# CC23x0 register map
File version: 1.1
CPU: CM0+ r0p4, little endian, no MPU, no FPU, VTOR, 3 interrupt priority bits
Registers are 32-bit, read-write, reset 0x0 unless marked. A register's access mark holds for its fields unless they carry their own. Offsets are from the block's base; [hi:lo] are bit positions; {n}, {i} and the like mark numbered series; 'fields as' and 'values as' point back to an identical list.

## LRFDMDM32 (part 2 of 2)
Base 0x40082400
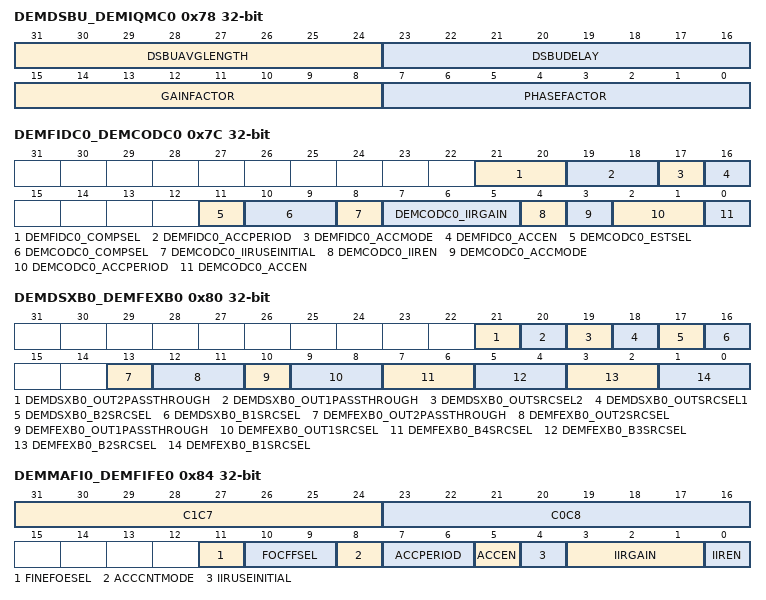
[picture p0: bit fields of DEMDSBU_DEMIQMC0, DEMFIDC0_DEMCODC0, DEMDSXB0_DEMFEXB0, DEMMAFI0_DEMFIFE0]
0x78 DEMDSBU_DEMIQMC0 — Internal. Only to be used through TI provided API.
  [all] fields
    255=ALLONES (Internal. Only to be used through TI provided API.); 0=ALLZEROS (Internal. Only to be used through TI provided API.)
  [31:24] DSBUAVGLENGTH — Internal. Only to be used through TI provided API.
  [23:16] DSBUDELAY — Internal. Only to be used through TI provided API.
  [15:8] GAINFACTOR — Internal. Only to be used through TI provided API.
  [7:0] PHASEFACTOR — Internal. Only to be used through TI provided API.
0x7C DEMFIDC0_DEMCODC0 — Internal. Only to be used through TI provided API.
  [21:20] DEMFIDC0_COMPSEL — Internal. Only to be used through TI provided API.
    2=ACC (Internal. Only to be used through TI provided API.); 0=MANUAL (Internal. Only to be used through TI provided API.)
  [19:18] DEMFIDC0_ACCPERIOD — Internal. Only to be used through TI provided API.
    3=SMPL512 (Internal. Only to be used through TI provided API.); 2=SMPL128 (Internal. Only to be used through TI provided API.); 1=SMPL32 (Internal. Only to be used through TI provided API.); 0=SMPL8 (Internal. Only to be used through TI provided API.)
  [17] DEMFIDC0_ACCMODE — Internal. Only to be used through TI provided API.
    1=CONT (Internal. Only to be used through TI provided API.); 0=SINGLE (Internal. Only to be used through TI provided API.)
  [16] DEMFIDC0_ACCEN — Internal. Only to be used through TI provided API.
    1=ON (Internal. Only to be used through TI provided API.); 0=OFF (Internal. Only to be used through TI provided API.)
  [11] DEMCODC0_ESTSEL — Internal. Only to be used through TI provided API.
    1=IIR (Internal. Only to be used through TI provided API.); 0=ACC (Internal. Only to be used through TI provided API.)
  [10:9] DEMCODC0_COMPSEL — Internal. Only to be used through TI provided API.
    3=IIR (Internal. Only to be used through TI provided API.); 2=ACC (Internal. Only to be used through TI provided API.); 0=MANUAL (Internal. Only to be used through TI provided API.)
  [8] DEMCODC0_IIRUSEINITIAL — Internal. Only to be used through TI provided API.
    1=EN (Internal. Only to be used through TI provided API.); 0=DIS (Internal. Only to be used through TI provided API.)
  [7:5] DEMCODC0_IIRGAIN — Internal. Only to be used through TI provided API.
    7=DIV1024 (Internal. Only to be used through TI provided API.); 6=DIV512 (Internal. Only to be used through TI provided API.); 5=DIV256 (Internal. Only to be used through TI provided API.); 4=DIV128 (Internal. Only to be used through TI provided API.); 3=DIV64 (Internal. Only to be used through TI provided API.); 2=DIV32 (Internal. Only to be used through TI provided API.); 1=DIV16 (Internal. Only to be used through TI provided API.); 0=OFF (Internal. Only to be used through TI provided API.)
  [4] DEMCODC0_IIREN — Internal. Only to be used through TI provided API.
    values as DEMFIDC0_ACCEN
  [3] DEMCODC0_ACCMODE — Internal. Only to be used through TI provided API.
    values as DEMFIDC0_ACCMODE
  [2:1] DEMCODC0_ACCPERIOD — Internal. Only to be used through TI provided API.
    values as DEMFIDC0_ACCPERIOD
  [0] DEMCODC0_ACCEN — Internal. Only to be used through TI provided API.
    values as DEMFIDC0_ACCEN
0x80 DEMDSXB0_DEMFEXB0 — Internal. Only to be used through TI provided API.
  [21] DEMDSXB0_OUT2PASSTHROUGH — Internal. Only to be used through TI provided API.
    1=ONE (Internal. Only to be used through TI provided API.); 0=ZERO (Internal. Only to be used through TI provided API.)
  [20] DEMDSXB0_OUT1PASSTHROUGH — Internal. Only to be used through TI provided API.
    values as DEMDSXB0_OUT2PASSTHROUGH
  [19] DEMDSXB0_OUTSRCSEL2 — Internal. Only to be used through TI provided API.
    1=MAFI (Internal. Only to be used through TI provided API.); 0=FIFE (Internal. Only to be used through TI provided API.)
  [18] DEMDSXB0_OUTSRCSEL1 — Internal. Only to be used through TI provided API.
    values as DEMDSXB0_OUTSRCSEL2
  [17] DEMDSXB0_B2SRCSEL — Internal. Only to be used through TI provided API.
    1=FIFE (Internal. Only to be used through TI provided API.); 0=INPUT (Internal. Only to be used through TI provided API.)
  [16] DEMDSXB0_B1SRCSEL — Internal. Only to be used through TI provided API.
    1=MAFI (Internal. Only to be used through TI provided API.); 0=INPUT (Internal. Only to be used through TI provided API.)
  [13] DEMFEXB0_OUT2PASSTHROUGH — Internal. Only to be used through TI provided API.
    values as DEMDSXB0_OUT2PASSTHROUGH
  [12:11] DEMFEXB0_OUT2SRCSEL — Internal. Only to be used through TI provided API.
    2=BDE1 (Internal. Only to be used through TI provided API.); 1=CMIX (Internal. Only to be used through TI provided API.); 0=CODC (Internal. Only to be used through TI provided API.)
  [10] DEMFEXB0_OUT1PASSTHROUGH — Internal. Only to be used through TI provided API.
    values as DEMDSXB0_OUT2PASSTHROUGH
  [9:8] DEMFEXB0_OUT1SRCSEL — Internal. Only to be used through TI provided API.
    values as DEMFEXB0_OUT2SRCSEL
  [7:6] DEMFEXB0_B4SRCSEL — Internal. Only to be used through TI provided API.
    3=ONES (Internal. Only to be used through TI provided API.); 0=ZEROS (Internal. Only to be used through TI provided API.)
  [5:4] DEMFEXB0_B3SRCSEL — Internal. Only to be used through TI provided API.
    2=CMIX (Internal. Only to be used through TI provided API.); 1=CODC (Internal. Only to be used through TI provided API.); 0=INPUT (Internal. Only to be used through TI provided API.)
  [3:2] DEMFEXB0_B2SRCSEL — Internal. Only to be used through TI provided API.
    2=BDE1 (Internal. Only to be used through TI provided API.); 1=CODC (Internal. Only to be used through TI provided API.); 0=INPUT (Internal. Only to be used through TI provided API.)
  [1:0] DEMFEXB0_B1SRCSEL — Internal. Only to be used through TI provided API.
    2=BDE1 (Internal. Only to be used through TI provided API.); 1=CMIX (Internal. Only to be used through TI provided API.); 0=INPUT (Internal. Only to be used through TI provided API.)
0x84 DEMMAFI0_DEMFIFE0 — Internal. Only to be used through TI provided API.
  [31:24] C1C7 — Internal. Only to be used through TI provided API.
    values as the fields of DEMDSBU_DEMIQMC0
  [23:16] C0C8 — Internal. Only to be used through TI provided API.
    values as the fields of DEMDSBU_DEMIQMC0
  [11] FINEFOESEL — Internal. Only to be used through TI provided API.
    1=ACC (Internal. Only to be used through TI provided API.); 0=IIR (Internal. Only to be used through TI provided API.)
  [10:9] FOCFFSEL — Internal. Only to be used through TI provided API.
    2=MANUAL (Internal. Only to be used through TI provided API.); 1=ACC (Internal. Only to be used through TI provided API.); 0=IIR (Internal. Only to be used through TI provided API.)
  [8] ACCCNTMODE — Internal. Only to be used through TI provided API.
    values as DEMFIDC0_DEMCODC0.DEMFIDC0_ACCMODE
  [7:6] ACCPERIOD — Internal. Only to be used through TI provided API.
    3=PER512 (Internal. Only to be used through TI provided API.); 2=PER256 (Internal. Only to be used through TI provided API.); 1=PER128 (Internal. Only to be used through TI provided API.); 0=PER64 (Internal. Only to be used through TI provided API.)
  [5] ACCEN — Internal. Only to be used through TI provided API.
    values as DEMFIDC0_DEMCODC0.DEMFIDC0_ACCEN
  [4] IIRUSEINITIAL — Internal. Only to be used through TI provided API.
    values as DEMFIDC0_DEMCODC0.DEMCODC0_IIRUSEINITIAL
  [3:1] IIRGAIN — Internal. Only to be used through TI provided API.
    values as DEMFIDC0_DEMCODC0.DEMCODC0_IIRGAIN
  [0] IIREN — Internal. Only to be used through TI provided API.
    values as DEMFIDC0_DEMCODC0.DEMFIDC0_ACCEN
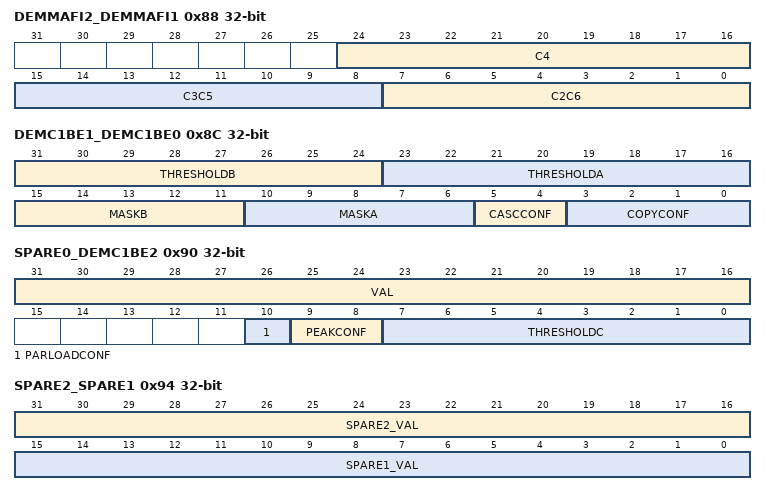
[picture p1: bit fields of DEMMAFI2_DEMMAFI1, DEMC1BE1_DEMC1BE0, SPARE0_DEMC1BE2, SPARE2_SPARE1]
0x88 DEMMAFI2_DEMMAFI1 — Internal. Only to be used through TI provided API.
  [24:16] C4 — Internal. Only to be used through TI provided API.
    0x1FF=ALLONES (Internal. Only to be used through TI provided API.); 0=ALLZEROS (Internal. Only to be used through TI provided API.)
  [15:8] C3C5 — Internal. Only to be used through TI provided API.
    values as the fields of DEMDSBU_DEMIQMC0
  [7:0] C2C6 — Internal. Only to be used through TI provided API.
    values as the fields of DEMDSBU_DEMIQMC0
0x8C DEMC1BE1_DEMC1BE0 — Internal. Only to be used through TI provided API.
  [31:24] THRESHOLDB — Internal. Only to be used through TI provided API.
    values as the fields of DEMDSBU_DEMIQMC0
  [23:16] THRESHOLDA — Internal. Only to be used through TI provided API.
    values as the fields of DEMDSBU_DEMIQMC0
  [15:11] MASKB — Internal. Only to be used through TI provided API.
    31=ALLONES (Internal. Only to be used through TI provided API.); 0=ALLZEROS (Internal. Only to be used through TI provided API.)
  [10:6] MASKA — Internal. Only to be used through TI provided API.
    values as MASKB
  [5:4] CASCCONF — Internal. Only to be used through TI provided API.
    2=PARALLEL (Internal. Only to be used through TI provided API.); 1=SERIAL (Internal. Only to be used through TI provided API.); 0=SINGLE (Internal. Only to be used through TI provided API.)
  [3:0] COPYCONF — Internal. Only to be used through TI provided API.
    15=ALLONES (Internal. Only to be used through TI provided API.); 0=ALLZEROS (Internal. Only to be used through TI provided API.)
0x90 SPARE0_DEMC1BE2 — Internal. Only to be used through TI provided API.
  [31:16] VAL — Internal. Only to be used through TI provided API.
    0xFFFF=ALLONES (Internal. Only to be used through TI provided API.); 0=ALLZEROS (Internal. Only to be used through TI provided API.)
  [10] PARLOADCONF — Internal. Only to be used through TI provided API.
    1=ATOD (Internal. Only to be used through TI provided API.); 0=ATOB (Internal. Only to be used through TI provided API.)
  [9:8] PEAKCONF — Internal. Only to be used through TI provided API.
    2=BESTAB (Internal. Only to be used through TI provided API.); 1=BEST (Internal. Only to be used through TI provided API.); 0=THRESH (Internal. Only to be used through TI provided API.)
  [7:0] THRESHOLDC — Internal. Only to be used through TI provided API.
    values as the fields of DEMDSBU_DEMIQMC0
0x94 SPARE2_SPARE1 — Internal. Only to be used through TI provided API.
  [31:16] SPARE2_VAL — Internal. Only to be used through TI provided API.
    values as SPARE0_DEMC1BE2.VAL
  [15:0] SPARE1_VAL — Internal. Only to be used through TI provided API.
    values as SPARE0_DEMC1BE2.VAL
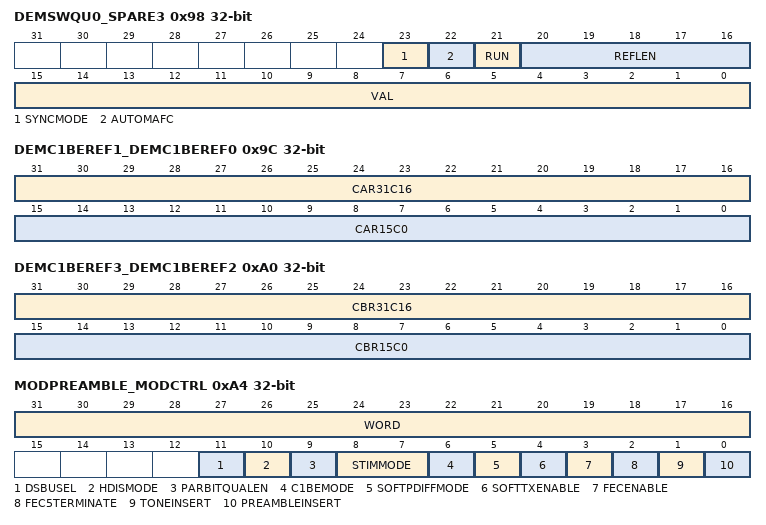
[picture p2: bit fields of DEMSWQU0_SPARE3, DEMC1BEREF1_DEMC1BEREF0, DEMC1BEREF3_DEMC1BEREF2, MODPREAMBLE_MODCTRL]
0x98 DEMSWQU0_SPARE3 — Internal. Only to be used through TI provided API.
  [23] SYNCMODE — Internal. Only to be used through TI provided API.
    values as DEMDSXB0_DEMFEXB0.DEMDSXB0_OUT2PASSTHROUGH
  [22] AUTOMAFC — Internal. Only to be used through TI provided API.
    values as DEMFIDC0_DEMCODC0.DEMFIDC0_ACCEN
  [21] RUN — Internal. Only to be used through TI provided API.
    values as DEMFIDC0_DEMCODC0.DEMFIDC0_ACCEN
  [20:16] REFLEN — Internal. Only to be used through TI provided API.
    values as DEMC1BE1_DEMC1BE0.MASKB
  [15:0] VAL — Internal. Only to be used through TI provided API.
    values as SPARE0_DEMC1BE2.VAL
0x9C DEMC1BEREF1_DEMC1BEREF0 — Internal. Only to be used through TI provided API.
  [31:16] CAR31C16 — Internal. Only to be used through TI provided API.
    values as SPARE0_DEMC1BE2.VAL
  [15:0] CAR15C0 — Internal. Only to be used through TI provided API.
    values as SPARE0_DEMC1BE2.VAL
0xA0 DEMC1BEREF3_DEMC1BEREF2 — Internal. Only to be used through TI provided API.
  [31:16] CBR31C16 — Internal. Only to be used through TI provided API.
    values as SPARE0_DEMC1BE2.VAL
  [15:0] CBR15C0 — Internal. Only to be used through TI provided API.
    values as SPARE0_DEMC1BE2.VAL
0xA4 MODPREAMBLE_MODCTRL — Internal. Only to be used through TI provided API.
  [31:16] WORD — Internal. Only to be used through TI provided API.
    values as SPARE0_DEMC1BE2.VAL
  [11] DSBUSEL — Internal. Only to be used through TI provided API.
    values as DEMDSXB0_DEMFEXB0.DEMDSXB0_OUT2PASSTHROUGH
  [10] HDISMODE — Internal. Only to be used through TI provided API.
    values as DEMFIDC0_DEMCODC0.DEMCODC0_IIRUSEINITIAL
  [9] PARBITQUALEN — Internal. Only to be used through TI provided API.
    values as DEMFIDC0_DEMCODC0.DEMFIDC0_ACCEN
  [8:7] STIMMODE — Internal. Only to be used through TI provided API.
    2=EARLY (Internal. Only to be used through TI provided API.); 1=LATE (Internal. Only to be used through TI provided API.); 0=NORMAL (Internal. Only to be used through TI provided API.)
  [6] C1BEMODE — Internal. Only to be used through TI provided API.
    1=EARLYLATE (Internal. Only to be used through TI provided API.); 0=NORMAL (Internal. Only to be used through TI provided API.)
  [5] SOFTPDIFFMODE — Internal. Only to be used through TI provided API.
    values as DEMFIDC0_DEMCODC0.DEMCODC0_IIRUSEINITIAL
  [4] SOFTTXENABLE — Internal. Only to be used through TI provided API.
    values as DEMFIDC0_DEMCODC0.DEMFIDC0_ACCEN
  [3] FECENABLE — Internal. Only to be used through TI provided API.
    values as DEMFIDC0_DEMCODC0.DEMFIDC0_ACCEN
  [2] FEC5TERMINATE — Internal. Only to be used through TI provided API.
    values as DEMFIDC0_DEMCODC0.DEMFIDC0_ACCEN
  [1] TONEINSERT — Internal. Only to be used through TI provided API.
    values as DEMFIDC0_DEMCODC0.DEMCODC0_IIRUSEINITIAL
  [0] PREAMBLEINSERT — Internal. Only to be used through TI provided API.
    values as DEMFIDC0_DEMCODC0.DEMCODC0_IIRUSEINITIAL
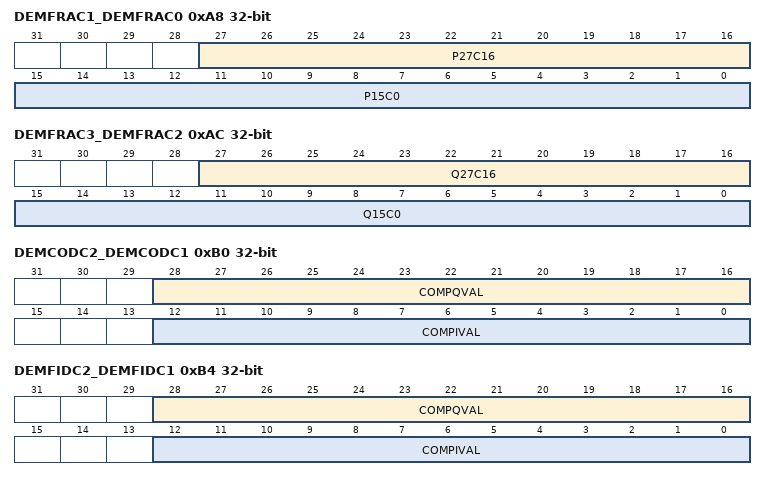
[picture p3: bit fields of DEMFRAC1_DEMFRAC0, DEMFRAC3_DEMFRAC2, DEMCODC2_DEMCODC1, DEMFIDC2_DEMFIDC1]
0xA8 DEMFRAC1_DEMFRAC0 — Internal. Only to be used through TI provided API.
  [27:16] P27C16 — Internal. Only to be used through TI provided API.
    0xFFF=ALLONES (Internal. Only to be used through TI provided API.); 0=ALLZEROS (Internal. Only to be used through TI provided API.)
  [15:0] P15C0 — Internal. Only to be used through TI provided API.
    values as SPARE0_DEMC1BE2.VAL
0xAC DEMFRAC3_DEMFRAC2 — Internal. Only to be used through TI provided API.
  [27:16] Q27C16 — Internal. Only to be used through TI provided API.
    values as DEMFRAC1_DEMFRAC0.P27C16
  [15:0] Q15C0 — Internal. Only to be used through TI provided API.
    values as SPARE0_DEMC1BE2.VAL
0xB0 DEMCODC2_DEMCODC1 — Internal. Only to be used through TI provided API.
  [28:16] COMPQVAL — Internal. Only to be used through TI provided API.
    0x1FFF=ALLONES (Internal. Only to be used through TI provided API.); 0=ALLZEROS (Internal. Only to be used through TI provided API.)
  [12:0] COMPIVAL — Internal. Only to be used through TI provided API.
    values as COMPQVAL
0xB4 DEMFIDC2_DEMFIDC1 — Internal. Only to be used through TI provided API.
  fields as DEMCODC2_DEMCODC1
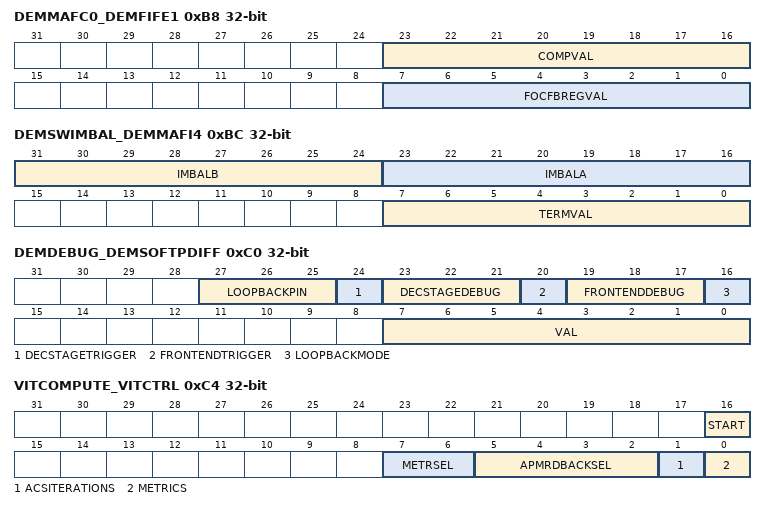
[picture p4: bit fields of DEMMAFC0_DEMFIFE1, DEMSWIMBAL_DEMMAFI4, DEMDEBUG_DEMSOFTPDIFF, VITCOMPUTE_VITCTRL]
0xB8 DEMMAFC0_DEMFIFE1 — Internal. Only to be used through TI provided API.
  [23:16] COMPVAL — Internal. Only to be used through TI provided API.
    values as the fields of DEMDSBU_DEMIQMC0
  [7:0] FOCFBREGVAL — Internal. Only to be used through TI provided API.
    values as the fields of DEMDSBU_DEMIQMC0
0xBC DEMSWIMBAL_DEMMAFI4 — Internal. Only to be used through TI provided API.
  [all] fields
    values as the fields of DEMDSBU_DEMIQMC0
  [31:24] IMBALB — Internal. Only to be used through TI provided API.
  [23:16] IMBALA — Internal. Only to be used through TI provided API.
  [7:0] TERMVAL — Internal. Only to be used through TI provided API.
0xC0 DEMDEBUG_DEMSOFTPDIFF — Internal. Only to be used through TI provided API.
  [27:25] LOOPBACKPIN — Internal. Only to be used through TI provided API.
    {v}=GPI{v} (Internal. Only to be used through TI provided API.) (v=0..7)
  [24] DECSTAGETRIGGER — Internal. Only to be used through TI provided API.
    values as DEMDSXB0_DEMFEXB0.DEMDSXB0_OUT2PASSTHROUGH
  [23:21] DECSTAGEDEBUG — Internal. Only to be used through TI provided API.
    7=SOFD (Internal. Only to be used through TI provided API.); 6=STIM (Internal. Only to be used through TI provided API.); 5=MAFC (Internal. Only to be used through TI provided API.); 4=C1BE (Internal. Only to be used through TI provided API.); 3=MAFI (Internal. Only to be used through TI provided API.); 2=FIFE (Internal. Only to be used through TI provided API.); 1=PDIF (Internal. Only to be used through TI provided API.); 0=NOSEL (Internal. Only to be used through TI provided API.)
  [20] FRONTENDTRIGGER — Internal. Only to be used through TI provided API.
    values as DEMDSXB0_DEMFEXB0.DEMDSXB0_OUT2PASSTHROUGH
  [19:17] FRONTENDDEBUG — Internal. Only to be used through TI provided API.
    7=FIDC (Internal. Only to be used through TI provided API.); 6=FRAC (Internal. Only to be used through TI provided API.); 5=CHFI (Internal. Only to be used through TI provided API.); 4=BDE2 (Internal. Only to be used through TI provided API.); 3=FEXB2 (Internal. Only to be used through TI provided API.); 2=BDE1 (Internal. Only to be used through TI provided API.); 1=IQMC (Internal. Only to be used through TI provided API.); 0=NOSEL (Internal. Only to be used through TI provided API.)
  [16] LOOPBACKMODE — Internal. Only to be used through TI provided API.
    values as DEMDSXB0_DEMFEXB0.DEMDSXB0_OUT2PASSTHROUGH
  [7:0] VAL — Internal. Only to be used through TI provided API.
    values as the fields of DEMDSBU_DEMIQMC0
0xC4 VITCOMPUTE_VITCTRL — Internal. Only to be used through TI provided API.
  [16] START wo — Internal. Only to be used through TI provided API.
    values as DEMDSXB0_DEMFEXB0.DEMDSXB0_OUT2PASSTHROUGH
  [7:6] METRSEL — Internal. Only to be used through TI provided API.
    3=MLSE (Internal. Only to be used through TI provided API.); 2=SOFD (Internal. Only to be used through TI provided API.); 1=PHAC (Internal. Only to be used through TI provided API.); 0=MET5M (Internal. Only to be used through TI provided API.)
  [5:2] APMRDBACKSEL — Internal. Only to be used through TI provided API.
    {v}=APM{v-8} (Internal. Only to be used through TI provided API.) (v=8..15); 0=NOSEL (Internal. Only to be used through TI provided API.)
  [1] ACSITERATIONS — Internal. Only to be used through TI provided API.
    1=CODE23 (Internal. Only to be used through TI provided API.); 0=CODE12 (Internal. Only to be used through TI provided API.)
  [0] METRICS — Internal. Only to be used through TI provided API.
    1=SOFT (Internal. Only to be used through TI provided API.); 0=HW (Internal. Only to be used through TI provided API.)
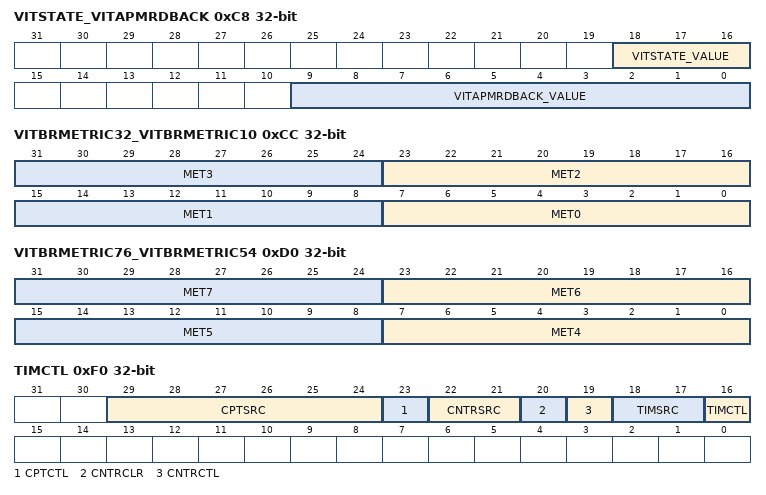
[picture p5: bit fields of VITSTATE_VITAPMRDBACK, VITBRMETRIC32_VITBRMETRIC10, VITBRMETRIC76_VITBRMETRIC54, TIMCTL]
0xC8 VITSTATE_VITAPMRDBACK ro — Internal. Only to be used through TI provided API.
  [18:16] VITSTATE_VALUE — Internal. Only to be used through TI provided API.
    7=ALLONES (Internal. Only to be used through TI provided API.); 0=ALLZEROS (Internal. Only to be used through TI provided API.)
  [9:0] VITAPMRDBACK_VALUE — Internal. Only to be used through TI provided API.
    0x3FF=ALLONES (Internal. Only to be used through TI provided API.); 0=ALLZEROS (Internal. Only to be used through TI provided API.)
0xCC VITBRMETRIC32_VITBRMETRIC10 — Internal. Only to be used through TI provided API.
  [all] fields
    values as the fields of DEMDSBU_DEMIQMC0
  [8n+7:8n] MET{n} (n=0..3) — Internal. Only to be used through TI provided API.
0xD0 VITBRMETRIC76_VITBRMETRIC54 — Internal. Only to be used through TI provided API.
  [all] fields
    values as the fields of DEMDSBU_DEMIQMC0
  [8n-25:8n-32] MET{n} (n=4..7) — Internal. Only to be used through TI provided API.
0xF0 TIMCTL — Internal. Only to be used through TI provided API.
  [29:24] CPTSRC — Internal. Only to be used through TI provided API.
    63=ALLONES (Internal. Only to be used through TI provided API.); 0=ALLZEROS (Internal. Only to be used through TI provided API.)
  [23] CPTCTL — Internal. Only to be used through TI provided API.
    values as DEMFIDC0_DEMCODC0.DEMCODC0_IIRUSEINITIAL
  [22:21] CNTRSRC — Internal. Only to be used through TI provided API.
    3=CLK4BAUDF (Internal. Only to be used through TI provided API.); 2=CLK4BAUD (Internal. Only to be used through TI provided API.); 1=CLKBAUD (Internal. Only to be used through TI provided API.); 0=CLK (Internal. Only to be used through TI provided API.)
  [20] CNTRCLR — Internal. Only to be used through TI provided API.
    values as DEMDSXB0_DEMFEXB0.DEMDSXB0_OUT2PASSTHROUGH
  [19] CNTRCTL — Internal. Only to be used through TI provided API.
    values as DEMDSXB0_DEMFEXB0.DEMDSXB0_OUT2PASSTHROUGH
  [18:17] TIMSRC — Internal. Only to be used through TI provided API.
    values as CNTRSRC
  [16] TIMCTL — Internal. Only to be used through TI provided API.
    values as DEMFIDC0_DEMCODC0.DEMCODC0_IIRUSEINITIAL
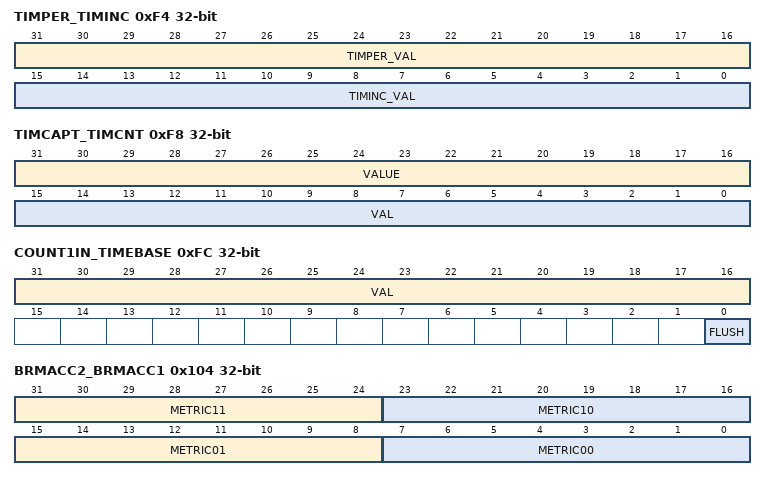
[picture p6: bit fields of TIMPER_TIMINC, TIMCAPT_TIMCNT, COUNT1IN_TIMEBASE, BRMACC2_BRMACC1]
0xF4 TIMPER_TIMINC — Internal. Only to be used through TI provided API.
  [31:16] TIMPER_VAL — Internal. Only to be used through TI provided API.
    values as SPARE0_DEMC1BE2.VAL
  [15:0] TIMINC_VAL — Internal. Only to be used through TI provided API.
    values as SPARE0_DEMC1BE2.VAL
0xF8 TIMCAPT_TIMCNT ro — Internal. Only to be used through TI provided API.
  [31:16] VALUE — Internal. Only to be used through TI provided API.
    values as SPARE0_DEMC1BE2.VAL
  [15:0] VAL — Internal. Only to be used through TI provided API.
    values as SPARE0_DEMC1BE2.VAL
0xFC COUNT1IN_TIMEBASE wo — Internal. Only to be used through TI provided API.
  [31:16] VAL — Internal. Only to be used through TI provided API.
    values as SPARE0_DEMC1BE2.VAL
  [0] FLUSH — Internal. Only to be used through TI provided API.
    values as DEMDSXB0_DEMFEXB0.DEMDSXB0_OUT2PASSTHROUGH
0x100 COUNT1RES ro — Internal. Only to be used through TI provided API.
  [4:0] VAL
    values as DEMC1BE1_DEMC1BE0.MASKB
0x104 BRMACC2_BRMACC1 ro — Internal. Only to be used through TI provided API.
  [all] fields
    values as the fields of DEMDSBU_DEMIQMC0
  [31:24] METRIC11 — Internal. Only to be used through TI provided API.
  [23:16] METRIC10 — Internal. Only to be used through TI provided API.
  [15:8] METRIC01 — Internal. Only to be used through TI provided API.
  [7:0] METRIC00 — Internal. Only to be used through TI provided API.
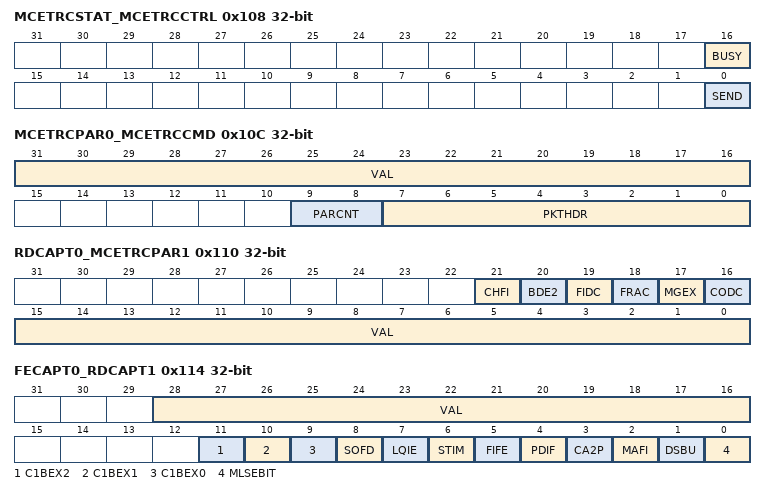
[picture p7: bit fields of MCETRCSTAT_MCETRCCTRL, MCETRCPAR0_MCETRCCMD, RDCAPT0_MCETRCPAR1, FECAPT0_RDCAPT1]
0x108 MCETRCSTAT_MCETRCCTRL wo — Internal. Only to be used through TI provided API.
  [16] BUSY ro — Internal. Only to be used through TI provided API.
    values as DEMDSXB0_DEMFEXB0.DEMDSXB0_OUT2PASSTHROUGH
  [0] SEND — Internal. Only to be used through TI provided API.
    values as DEMDSXB0_DEMFEXB0.DEMDSXB0_OUT2PASSTHROUGH
0x10C MCETRCPAR0_MCETRCCMD — Internal. Only to be used through TI provided API.
  [31:16] VAL — Internal. Only to be used through TI provided API.
    values as SPARE0_DEMC1BE2.VAL
  [9:8] PARCNT — Internal. Only to be used through TI provided API.
    3=ALLONES (Internal. Only to be used through TI provided API.); 0=ALLZEROS (Internal. Only to be used through TI provided API.)
  [7:0] PKTHDR — Internal. Only to be used through TI provided API.
    values as the fields of DEMDSBU_DEMIQMC0
0x110 RDCAPT0_MCETRCPAR1 — Internal. Only to be used through TI provided API.
  [21] CHFI wo — Internal. Only to be used through TI provided API.
    values as DEMDSXB0_DEMFEXB0.DEMDSXB0_OUT2PASSTHROUGH
  [20] BDE2 wo — Internal. Only to be used through TI provided API.
    values as DEMDSXB0_DEMFEXB0.DEMDSXB0_OUT2PASSTHROUGH
  [19] FIDC wo — Internal. Only to be used through TI provided API.
    values as DEMDSXB0_DEMFEXB0.DEMDSXB0_OUT2PASSTHROUGH
  [18] FRAC wo — Internal. Only to be used through TI provided API.
    values as DEMDSXB0_DEMFEXB0.DEMDSXB0_OUT2PASSTHROUGH
  [17] MGEX wo — Internal. Only to be used through TI provided API.
    values as DEMDSXB0_DEMFEXB0.DEMDSXB0_OUT2PASSTHROUGH
  [16] CODC wo — Internal. Only to be used through TI provided API.
    values as DEMDSXB0_DEMFEXB0.DEMDSXB0_OUT2PASSTHROUGH
  [15:0] VAL — Internal. Only to be used through TI provided API.
    values as SPARE0_DEMC1BE2.VAL
0x114 FECAPT0_RDCAPT1 wo — Internal. Only to be used through TI provided API.
  [28:16] VAL — Internal. Only to be used through TI provided API.
    values as DEMCODC2_DEMCODC1.COMPQVAL
  [11] C1BEX2 — Internal. Only to be used through TI provided API.
    values as DEMDSXB0_DEMFEXB0.DEMDSXB0_OUT2PASSTHROUGH
  [10] C1BEX1 — Internal. Only to be used through TI provided API.
    values as DEMDSXB0_DEMFEXB0.DEMDSXB0_OUT2PASSTHROUGH
  [9] C1BEX0 — Internal. Only to be used through TI provided API.
    values as DEMDSXB0_DEMFEXB0.DEMDSXB0_OUT2PASSTHROUGH
  [8] SOFD — Internal. Only to be used through TI provided API.
    values as DEMDSXB0_DEMFEXB0.DEMDSXB0_OUT2PASSTHROUGH
  [7] LQIE — Internal. Only to be used through TI provided API.
    values as DEMDSXB0_DEMFEXB0.DEMDSXB0_OUT2PASSTHROUGH
  [6] STIM — Internal. Only to be used through TI provided API.
    values as DEMDSXB0_DEMFEXB0.DEMDSXB0_OUT2PASSTHROUGH
  [5] FIFE — Internal. Only to be used through TI provided API.
    values as DEMDSXB0_DEMFEXB0.DEMDSXB0_OUT2PASSTHROUGH
  [4] PDIF — Internal. Only to be used through TI provided API.
    values as DEMDSXB0_DEMFEXB0.DEMDSXB0_OUT2PASSTHROUGH
  [3] CA2P — Internal. Only to be used through TI provided API.
    values as DEMDSXB0_DEMFEXB0.DEMDSXB0_OUT2PASSTHROUGH
  [2] MAFI — Internal. Only to be used through TI provided API.
    values as DEMDSXB0_DEMFEXB0.DEMDSXB0_OUT2PASSTHROUGH
  [1] DSBU — Internal. Only to be used through TI provided API.
    values as DEMDSXB0_DEMFEXB0.DEMDSXB0_OUT2PASSTHROUGH
  [0] MLSEBIT — Internal. Only to be used through TI provided API.
    values as DEMDSXB0_DEMFEXB0.DEMDSXB0_OUT2PASSTHROUGH
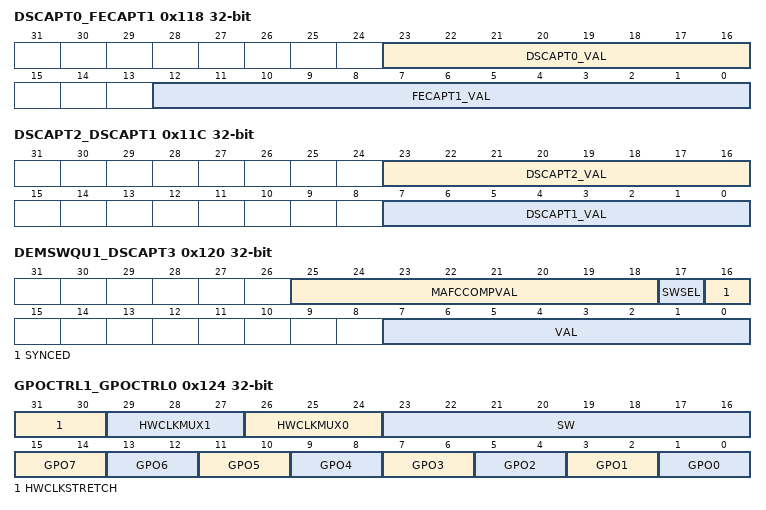
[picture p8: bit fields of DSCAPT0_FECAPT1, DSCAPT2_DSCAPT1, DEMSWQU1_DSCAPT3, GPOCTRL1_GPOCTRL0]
0x118 DSCAPT0_FECAPT1 — Internal. Only to be used through TI provided API.
  [23:16] DSCAPT0_VAL — Internal. Only to be used through TI provided API.
    values as the fields of DEMDSBU_DEMIQMC0
  [12:0] FECAPT1_VAL — Internal. Only to be used through TI provided API.
    values as DEMCODC2_DEMCODC1.COMPQVAL
0x11C DSCAPT2_DSCAPT1 — Internal. Only to be used through TI provided API.
  [23:16] DSCAPT2_VAL — Internal. Only to be used through TI provided API.
    values as the fields of DEMDSBU_DEMIQMC0
  [7:0] DSCAPT1_VAL — Internal. Only to be used through TI provided API.
    values as the fields of DEMDSBU_DEMIQMC0
0x120 DEMSWQU1_DSCAPT3 — Internal. Only to be used through TI provided API.
  [25:18] MAFCCOMPVAL ro — Internal. Only to be used through TI provided API.
    values as the fields of DEMDSBU_DEMIQMC0
  [17] SWSEL ro — Internal. Only to be used through TI provided API.
    1=B (Internal. Only to be used through TI provided API.); 0=A (Internal. Only to be used through TI provided API.)
  [16] SYNCED ro — Internal. Only to be used through TI provided API.
    values as DEMDSXB0_DEMFEXB0.DEMDSXB0_OUT2PASSTHROUGH
  [7:0] VAL — Internal. Only to be used through TI provided API.
    values as the fields of DEMDSBU_DEMIQMC0
0x124 GPOCTRL1_GPOCTRL0 — Internal. Only to be used through TI provided API.
  [31:30] HWCLKSTRETCH — Internal. Only to be used through TI provided API.
    values as DEMDSXB0_DEMFEXB0.DEMDSXB0_OUT2PASSTHROUGH
  [29:27] HWCLKMUX1 — Internal. Only to be used through TI provided API.
    values as DEMDSXB0_DEMFEXB0.DEMDSXB0_OUT2PASSTHROUGH
  [26:24] HWCLKMUX0 — Internal. Only to be used through TI provided API.
    values as DEMDSXB0_DEMFEXB0.DEMDSXB0_OUT2PASSTHROUGH
  [23:16] SW — Internal. Only to be used through TI provided API.
    values as DEMDSXB0_DEMFEXB0.DEMDSXB0_OUT2PASSTHROUGH
  [15:14] GPO7 — Internal. Only to be used through TI provided API.
    3=THREE (Internal. Only to be used through TI provided API.); 2=TWO (Internal. Only to be used through TI provided API.); 1=TOPSM_WAIT (Internal. Only to be used through TI provided API.); 0=SW7 (Internal. Only to be used through TI provided API.)
  [13:12] GPO6 — Internal. Only to be used through TI provided API.
    3=THREE (Internal. Only to be used through TI provided API.); 2=TWO (Internal. Only to be used through TI provided API.); 1=TRANSPARENT_OUT (Internal. Only to be used through TI provided API.); 0=SW6 (Internal. Only to be used through TI provided API.)
  [11:10] GPO5 — Internal. Only to be used through TI provided API.
    3=THREE (Internal. Only to be used through TI provided API.); 2=TWO (Internal. Only to be used through TI provided API.); 1=DEM_OUT_WORD (Internal. Only to be used through TI provided API.); 0=SW5 (Internal. Only to be used through TI provided API.)
  [9:8] GPO4 — Internal. Only to be used through TI provided API.
    3=THREE (Internal. Only to be used through TI provided API.); 2=TWO (Internal. Only to be used through TI provided API.); 1=CORR_PEAK_C (Internal. Only to be used through TI provided API.); 0=SW4 (Internal. Only to be used through TI provided API.)
  [7:6] GPO3 — Internal. Only to be used through TI provided API.
    3=THREE (Internal. Only to be used through TI provided API.); 2=TWO (Internal. Only to be used through TI provided API.); 1=CORR_PEAK_B (Internal. Only to be used through TI provided API.); 0=SW3 (Internal. Only to be used through TI provided API.)
  [5:4] GPO2 — Internal. Only to be used through TI provided API.
    3=THREE (Internal. Only to be used through TI provided API.); 2=TWO (Internal. Only to be used through TI provided API.); 1=CORR_PEAK_A (Internal. Only to be used through TI provided API.); 0=SW2 (Internal. Only to be used through TI provided API.)
  [3:2] GPO1 — Internal. Only to be used through TI provided API.
    3=THREE (Internal. Only to be used through TI provided API.); 2=TWO (Internal. Only to be used through TI provided API.); 1=HWCLK1 (Internal. Only to be used through TI provided API.); 0=SW1 (Internal. Only to be used through TI provided API.)
  [1:0] GPO0 — Internal. Only to be used through TI provided API.
    3=THREE (Internal. Only to be used through TI provided API.); 2=LOOPBACK (Internal. Only to be used through TI provided API.); 1=HWCLK0 (Internal. Only to be used through TI provided API.); 0=SW0 (Internal. Only to be used through TI provided API.)
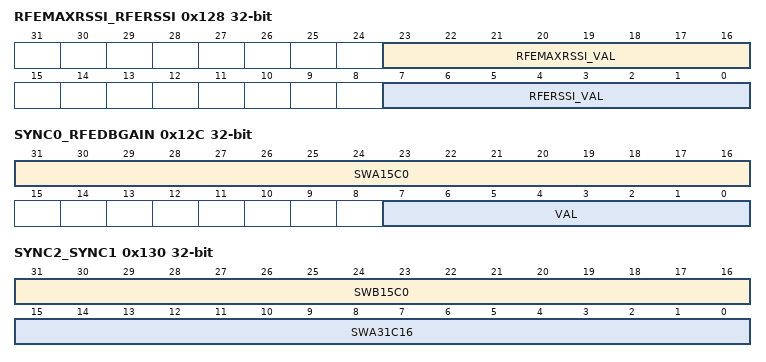
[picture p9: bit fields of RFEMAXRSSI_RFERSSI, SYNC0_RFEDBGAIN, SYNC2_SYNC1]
0x128 RFEMAXRSSI_RFERSSI ro — Internal. Only to be used through TI provided API.
  [23:16] RFEMAXRSSI_VAL — Internal. Only to be used through TI provided API.
    values as the fields of DEMDSBU_DEMIQMC0
  [7:0] RFERSSI_VAL — Internal. Only to be used through TI provided API.
    values as the fields of DEMDSBU_DEMIQMC0
0x12C SYNC0_RFEDBGAIN ro — Internal. Only to be used through TI provided API.
  [31:16] SWA15C0 — Internal. Only to be used through TI provided API.
    values as SPARE0_DEMC1BE2.VAL
  [7:0] VAL — Internal. Only to be used through TI provided API.
    values as the fields of DEMDSBU_DEMIQMC0
0x130 SYNC2_SYNC1 ro — Internal. Only to be used through TI provided API.
  [31:16] SWB15C0 — Internal. Only to be used through TI provided API.
    values as SPARE0_DEMC1BE2.VAL
  [15:0] SWA31C16 — Internal. Only to be used through TI provided API.
    values as SPARE0_DEMC1BE2.VAL
0x134 SYNC3 ro — Internal. Only to be used through TI provided API.
  [15:0] SWB31C16
    values as SPARE0_DEMC1BE2.VAL
